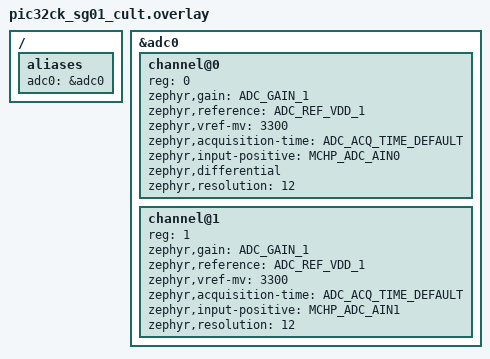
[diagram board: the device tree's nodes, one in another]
/*
 * SPDX-FileCopyrightText: Copyright (c) 2026 Microchip Technology Inc.
 *
 * SPDX-License-Identifier: Apache-2.0
 */

/* Provide (ADC+) to PA04 (EXT1 Pin 3) and (ADC-) to PA05 (EXT1 Pin 4),For differential Mode */

/ {
	aliases {
		adc0 = &adc0;
	};
};

&adc0 {
	#address-cells = <1>;
	#size-cells = <0>;
	status = "okay";

	channel@0 {
		reg = <0>;
		zephyr,gain = "ADC_GAIN_1";
		zephyr,reference = "ADC_REF_VDD_1";
		zephyr,vref-mv = <3300>;
		zephyr,acquisition-time = <ADC_ACQ_TIME_DEFAULT>;
		zephyr,input-positive = <MCHP_ADC_AIN0>;
		zephyr,differential;
		zephyr,resolution = <12>;
	};

	channel@1 {
		reg = <1>;
		zephyr,gain = "ADC_GAIN_1";
		zephyr,reference = "ADC_REF_VDD_1";
		zephyr,vref-mv = <3300>;
		zephyr,acquisition-time = <ADC_ACQ_TIME_DEFAULT>;
		zephyr,input-positive = <MCHP_ADC_AIN1>;
		/* zephyr,differential; */
		zephyr,resolution = <12>;
	};
};
